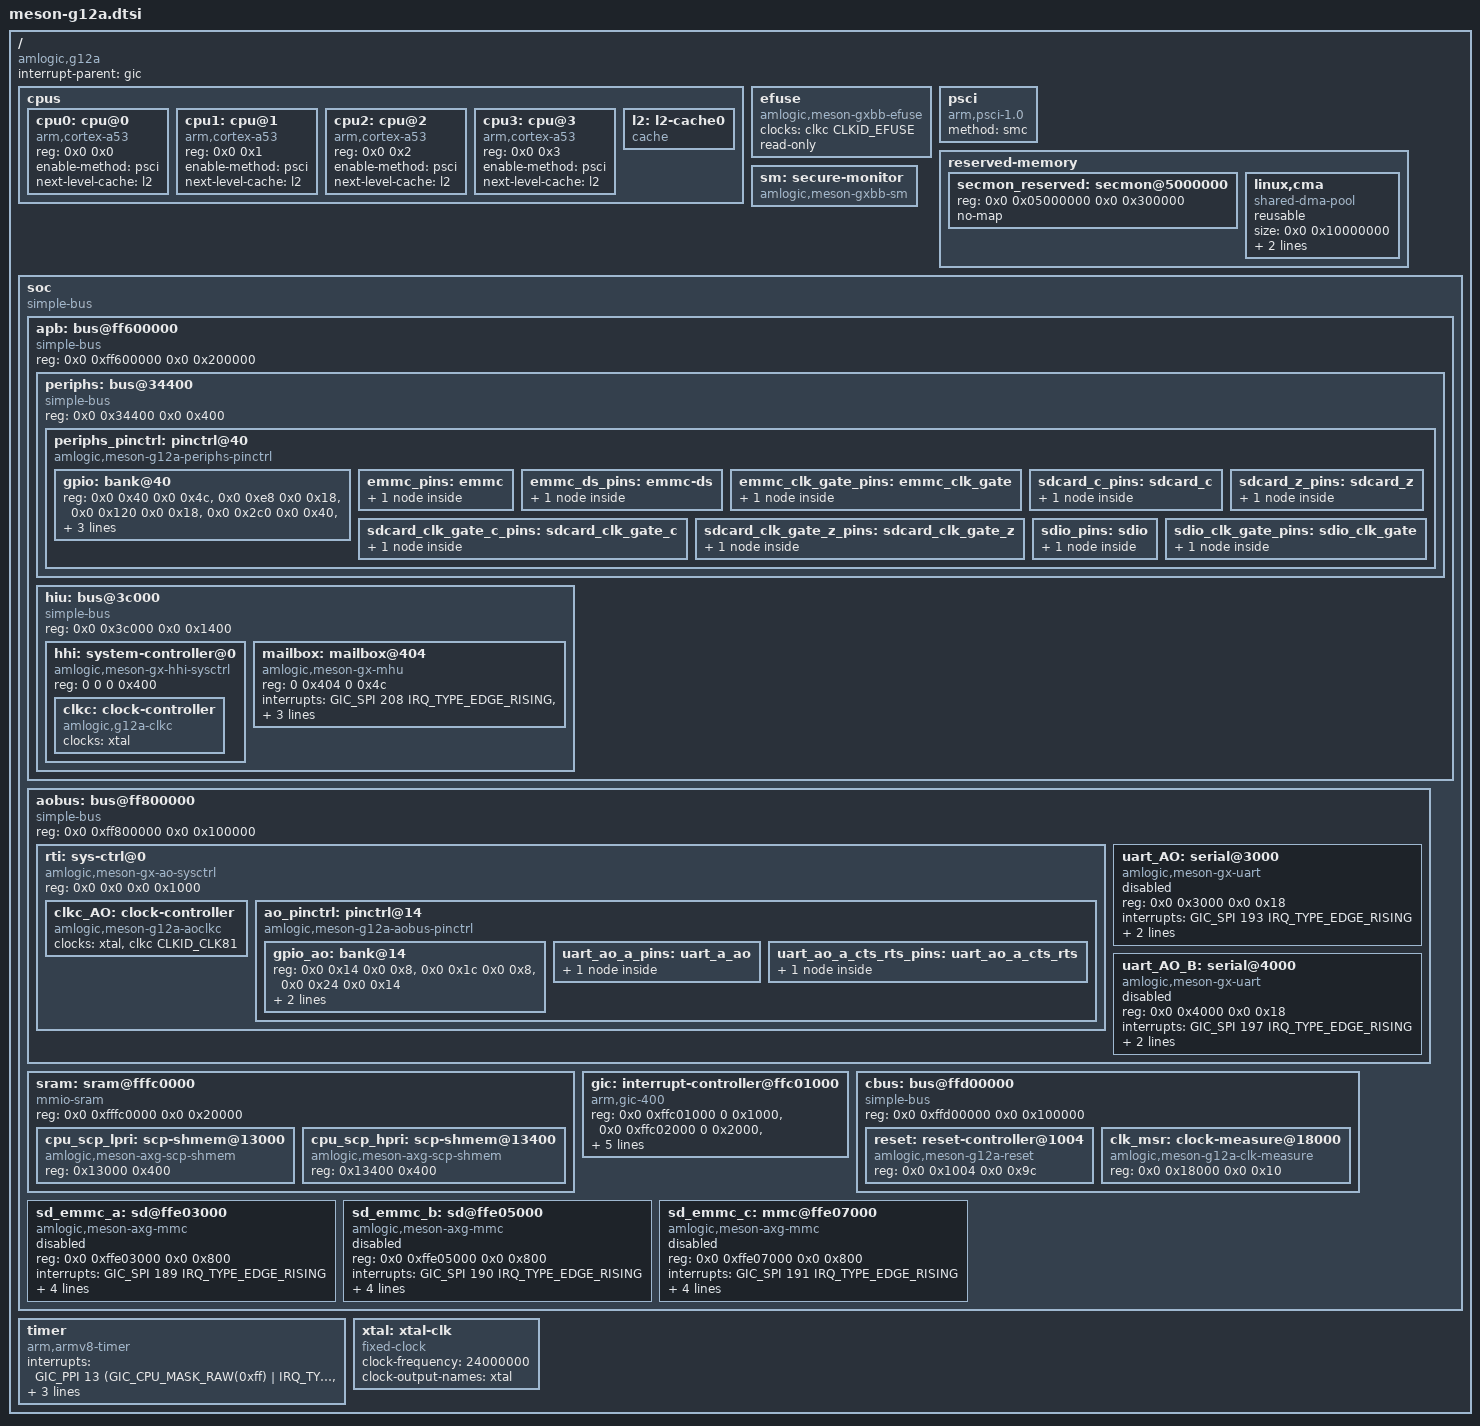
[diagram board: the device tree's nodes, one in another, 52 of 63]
// SPDX-License-Identifier: (GPL-2.0+ OR MIT)
/*
 * Copyright (c) 2018 Amlogic, Inc. All rights reserved.
 */

#include <dt-bindings/gpio/gpio.h>
#include <dt-bindings/clock/g12a-clkc.h>
#include <dt-bindings/gpio/gpio.h>
#include <dt-bindings/gpio/meson-g12a-gpio.h>
#include <dt-bindings/clock/g12a-aoclkc.h>
#include <dt-bindings/reset/g12a-aoclkc.h>
#include <dt-bindings/interrupt-controller/irq.h>
#include <dt-bindings/interrupt-controller/arm-gic.h>
#include <dt-bindings/reset/amlogic,meson-g12a-reset.h>

/ {
	compatible = "amlogic,g12a";

	interrupt-parent = <&gic>;
	#address-cells = <2>;
	#size-cells = <2>;

	cpus {
		#address-cells = <0x2>;
		#size-cells = <0x0>;

		cpu0: cpu@0 {
			device_type = "cpu";
			compatible = "arm,cortex-a53", "arm,armv8";
			reg = <0x0 0x0>;
			enable-method = "psci";
			next-level-cache = <&l2>;
		};

		cpu1: cpu@1 {
			device_type = "cpu";
			compatible = "arm,cortex-a53", "arm,armv8";
			reg = <0x0 0x1>;
			enable-method = "psci";
			next-level-cache = <&l2>;
		};

		cpu2: cpu@2 {
			device_type = "cpu";
			compatible = "arm,cortex-a53", "arm,armv8";
			reg = <0x0 0x2>;
			enable-method = "psci";
			next-level-cache = <&l2>;
		};

		cpu3: cpu@3 {
			device_type = "cpu";
			compatible = "arm,cortex-a53", "arm,armv8";
			reg = <0x0 0x3>;
			enable-method = "psci";
			next-level-cache = <&l2>;
		};

		l2: l2-cache0 {
			compatible = "cache";
		};
	};

	efuse: efuse {
		compatible = "amlogic,meson-gxbb-efuse";
		clocks = <&clkc CLKID_EFUSE>;
		#address-cells = <1>;
		#size-cells = <1>;
		read-only;
	};

	psci {
		compatible = "arm,psci-1.0";
		method = "smc";
	};

	reserved-memory {
		#address-cells = <2>;
		#size-cells = <2>;
		ranges;

		/* 3 MiB reserved for ARM Trusted Firmware (BL31) */
		secmon_reserved: secmon@5000000 {
			reg = <0x0 0x05000000 0x0 0x300000>;
			no-map;
		};

		linux,cma {
			compatible = "shared-dma-pool";
			reusable;
			size = <0x0 0x10000000>;
			alignment = <0x0 0x400000>;
			linux,cma-default;
		};
	};

	sm: secure-monitor {
		compatible = "amlogic,meson-gxbb-sm";
	};

	soc {
		compatible = "simple-bus";
		#address-cells = <2>;
		#size-cells = <2>;
		ranges;

		apb: bus@ff600000 {
			compatible = "simple-bus";
			reg = <0x0 0xff600000 0x0 0x200000>;
			#address-cells = <2>;
			#size-cells = <2>;
			ranges = <0x0 0x0 0x0 0xff600000 0x0 0x200000>;

			periphs: bus@34400 {
				compatible = "simple-bus";
				reg = <0x0 0x34400 0x0 0x400>;
				#address-cells = <2>;
				#size-cells = <2>;
				ranges = <0x0 0x0 0x0 0x34400 0x0 0x400>;

				periphs_pinctrl: pinctrl@40 {
					compatible = "amlogic,meson-g12a-periphs-pinctrl";
					#address-cells = <2>;
					#size-cells = <2>;
					ranges;

					gpio: bank@40 {
						reg = <0x0 0x40  0x0 0x4c>,
						      <0x0 0xe8  0x0 0x18>,
						      <0x0 0x120 0x0 0x18>,
						      <0x0 0x2c0 0x0 0x40>,
						      <0x0 0x340 0x0 0x1c>;
						reg-names = "gpio",
							    "pull",
							    "pull-enable",
							    "mux",
							    "ds";
						gpio-controller;
						#gpio-cells = <2>;
						gpio-ranges = <&periphs_pinctrl 0 0 86>;
					};

					emmc_pins: emmc {
						mux {
							groups = "emmc_nand_d0",
								 "emmc_nand_d1",
								 "emmc_nand_d2",
								 "emmc_nand_d3",
								 "emmc_nand_d4",
								 "emmc_nand_d5",
								 "emmc_nand_d6",
								 "emmc_nand_d7",
								 "emmc_clk",
								 "emmc_cmd";
							function = "emmc";
							bias-disable;
						};
					};

					emmc_ds_pins: emmc-ds {
						mux {
							groups = "emmc_nand_ds";
							function = "emmc";
							bias-disable;
						};
					};

					emmc_clk_gate_pins: emmc_clk_gate {
						mux {
							groups = "BOOT_8";
							function = "gpio_periphs";
							bias-pull-down;
						};
					};

					sdcard_c_pins: sdcard_c {
						mux {
							groups = "sdcard_d0_c",
								 "sdcard_d1_c",
								 "sdcard_d2_c",
								 "sdcard_d3_c",
								 "sdcard_cmd_c",
								 "sdcard_clk_c";
							function = "sdcard";
							bias-disable;
						};
					};

					sdcard_clk_gate_c_pins: sdcard_clk_gate_c {
						mux {
							groups = "GPIOC_4";
							function = "gpio_periphs";
							bias-pull-down;
						};
					};

					sdcard_z_pins: sdcard_z {
						mux {
							groups = "sdcard_d0_z",
								 "sdcard_d1_z",
								 "sdcard_d2_z",
								 "sdcard_d3_z",
								 "sdcard_cmd_z",
								 "sdcard_clk_z";
							function = "sdcard";
							bias-disable;
						};
					};

					sdcard_clk_gate_z_pins: sdcard_clk_gate_z {
						mux {
							groups = "GPIOZ_6";
							function = "gpio_periphs";
							bias-pull-down;
						};
					};

					sdio_pins: sdio {
						mux {
							groups = "sdio_d0",
								 "sdio_d1",
								 "sdio_d2",
								 "sdio_d3",
								 "sdio_cmd",
								 "sdio_clk";
							function = "sdio";
							bias-disable;
						};
					};

					sdio_clk_gate_pins: sdio_clk_gate {
						mux {
							groups = "GPIOX_4";
							function = "gpio_periphs";
							bias-pull-down;
						};
					};
				};
			};

			hiu: bus@3c000 {
				compatible = "simple-bus";
				reg = <0x0 0x3c000 0x0 0x1400>;
				#address-cells = <2>;
				#size-cells = <2>;
				ranges = <0x0 0x0 0x0 0x3c000 0x0 0x1400>;

				hhi: system-controller@0 {
					compatible = "amlogic,meson-gx-hhi-sysctrl",
						     "simple-mfd", "syscon";
					reg = <0 0 0 0x400>;

					clkc: clock-controller {
						compatible = "amlogic,g12a-clkc";
						#clock-cells = <1>;
						clocks = <&xtal>;
						clock-names = "xtal";
					};
				};

				mailbox: mailbox@404 {
					compatible = "amlogic,meson-gx-mhu",
						     "amlogic,meson-gxbb-mhu";
					reg = <0 0x404 0 0x4c>;
					interrupts = <GIC_SPI 208 IRQ_TYPE_EDGE_RISING>,
						     <GIC_SPI 209 IRQ_TYPE_EDGE_RISING>,
						     <GIC_SPI 210 IRQ_TYPE_EDGE_RISING>;
					clocks = <&clkc_AO CLKID_AO_MAILBOX>;
					clock-names = "pclk";
					#mbox-cells = <1>;
				};
			};
		};

		aobus: bus@ff800000 {
			compatible = "simple-bus";
			reg = <0x0 0xff800000 0x0 0x100000>;
			#address-cells = <2>;
			#size-cells = <2>;
			ranges = <0x0 0x0 0x0 0xff800000 0x0 0x100000>;

			rti: sys-ctrl@0 {
				compatible = "amlogic,meson-gx-ao-sysctrl",
					     "simple-mfd", "syscon";
				reg = <0x0 0x0 0x0 0x1000>;
				#address-cells = <2>;
				#size-cells = <2>;
				ranges = <0x0 0x0 0x0 0x0 0x0 0x1000>;

				clkc_AO: clock-controller {
					compatible = "amlogic,meson-g12a-aoclkc";
					#clock-cells = <1>;
					#reset-cells = <1>;
					clocks = <&xtal>, <&clkc CLKID_CLK81>;
					clock-names = "xtal", "mpeg-clk";
				};

				ao_pinctrl: pinctrl@14 {
					compatible = "amlogic,meson-g12a-aobus-pinctrl";
					#address-cells = <2>;
					#size-cells = <2>;
					ranges;

					gpio_ao: bank@14 {
						reg = <0x0 0x14 0x0 0x8>,
						      <0x0 0x1c 0x0 0x8>,
						      <0x0 0x24 0x0 0x14>;
						reg-names = "mux",
							    "ds",
							    "gpio";
						gpio-controller;
						#gpio-cells = <2>;
						gpio-ranges = <&ao_pinctrl 0 0 15>;
					};

					uart_ao_a_pins: uart_a_ao {
						mux {
							groups = "uart_ao_a_tx",
								 "uart_ao_a_rx";
							function = "uart_ao_a";
							bias-disable;
						};
					};

					uart_ao_a_cts_rts_pins: uart_ao_a_cts_rts {
						mux {
							groups = "uart_ao_a_cts",
								 "uart_ao_a_rts";
							function = "uart_ao_a";
							bias-disable;
						};
					};
				};
			};

			uart_AO: serial@3000 {
				compatible = "amlogic,meson-gx-uart",
					     "amlogic,meson-ao-uart";
				reg = <0x0 0x3000 0x0 0x18>;
				interrupts = <GIC_SPI 193 IRQ_TYPE_EDGE_RISING>;
				clocks = <&xtal>, <&clkc_AO CLKID_AO_UART>, <&xtal>;
				clock-names = "xtal", "pclk", "baud";
				reset = <&clkc_AO RESET_AO_UART>;
				status = "disabled";
			};

			uart_AO_B: serial@4000 {
				compatible = "amlogic,meson-gx-uart",
					     "amlogic,meson-ao-uart";
				reg = <0x0 0x4000 0x0 0x18>;
				interrupts = <GIC_SPI 197 IRQ_TYPE_EDGE_RISING>;
				clocks = <&xtal>, <&clkc_AO CLKID_AO_UART2>, <&xtal>;
				clock-names = "xtal", "pclk", "baud";
				reset = <&clkc_AO RESET_AO_UART2>;
				status = "disabled";
			};
		};

		sram: sram@fffc0000 {
			compatible = "mmio-sram";
			reg = <0x0 0xfffc0000 0x0 0x20000>;
			#address-cells = <1>;
			#size-cells = <1>;
			ranges = <0 0x0 0xfffc0000 0x20000>;

			cpu_scp_lpri: scp-shmem@13000 {
				compatible = "amlogic,meson-axg-scp-shmem";
				reg = <0x13000 0x400>;
			};

			cpu_scp_hpri: scp-shmem@13400 {
				compatible = "amlogic,meson-axg-scp-shmem";
				reg = <0x13400 0x400>;
			};
		};

		gic: interrupt-controller@ffc01000 {
			compatible = "arm,gic-400";
			reg = <0x0 0xffc01000 0 0x1000>,
			      <0x0 0xffc02000 0 0x2000>,
			      <0x0 0xffc04000 0 0x2000>,
			      <0x0 0xffc06000 0 0x2000>;
			interrupt-controller;
			interrupts = <GIC_PPI 9
				(GIC_CPU_MASK_SIMPLE(8) | IRQ_TYPE_LEVEL_HIGH)>;
			#interrupt-cells = <3>;
			#address-cells = <0>;
		};

		cbus: bus@ffd00000 {
			compatible = "simple-bus";
			reg = <0x0 0xffd00000 0x0 0x100000>;
			#address-cells = <2>;
			#size-cells = <2>;
			ranges = <0x0 0x0 0x0 0xffd00000 0x0 0x100000>;

			reset: reset-controller@1004 {
				compatible = "amlogic,meson-g12a-reset",
					     "amlogic,meson-axg-reset";
				reg = <0x0 0x1004 0x0 0x9c>;
				#reset-cells = <1>;
			};

			clk_msr: clock-measure@18000 {
				compatible = "amlogic,meson-g12a-clk-measure";
				reg = <0x0 0x18000 0x0 0x10>;
			};
		};

		sd_emmc_a: sd@ffe03000 {
			compatible = "amlogic,meson-axg-mmc";
			reg = <0x0 0xffe03000 0x0 0x800>;
			interrupts = <GIC_SPI 189 IRQ_TYPE_EDGE_RISING>;
			status = "disabled";
			clocks = <&clkc CLKID_SD_EMMC_A>,
				 <&clkc CLKID_SD_EMMC_A_CLK0>,
				 <&clkc CLKID_FCLK_DIV2>;
			clock-names = "core", "clkin0", "clkin1";
			resets = <&reset RESET_SD_EMMC_A>;
		};

		sd_emmc_b: sd@ffe05000 {
			compatible = "amlogic,meson-axg-mmc";
			reg = <0x0 0xffe05000 0x0 0x800>;
			interrupts = <GIC_SPI 190 IRQ_TYPE_EDGE_RISING>;
			status = "disabled";
			clocks = <&clkc CLKID_SD_EMMC_B>,
				 <&clkc CLKID_SD_EMMC_B_CLK0>,
				 <&clkc CLKID_FCLK_DIV2>;
			clock-names = "core", "clkin0", "clkin1";
			resets = <&reset RESET_SD_EMMC_B>;
		};

		sd_emmc_c: mmc@ffe07000 {
			compatible = "amlogic,meson-axg-mmc";
			reg = <0x0 0xffe07000 0x0 0x800>;
			interrupts = <GIC_SPI 191 IRQ_TYPE_EDGE_RISING>;
			status = "disabled";
			clocks = <&clkc CLKID_SD_EMMC_C>,
				 <&clkc CLKID_SD_EMMC_C_CLK0>,
				 <&clkc CLKID_FCLK_DIV2>;
			clock-names = "core", "clkin0", "clkin1";
			resets = <&reset RESET_SD_EMMC_C>;
		};
	};

	timer {
		compatible = "arm,armv8-timer";
		interrupts = <GIC_PPI 13
			(GIC_CPU_MASK_RAW(0xff) | IRQ_TYPE_LEVEL_LOW)>,
			     <GIC_PPI 14
			(GIC_CPU_MASK_RAW(0xff) | IRQ_TYPE_LEVEL_LOW)>,
			     <GIC_PPI 11
			(GIC_CPU_MASK_RAW(0xff) | IRQ_TYPE_LEVEL_LOW)>,
			     <GIC_PPI 10
			(GIC_CPU_MASK_RAW(0xff) | IRQ_TYPE_LEVEL_LOW)>;
	};

	xtal: xtal-clk {
		compatible = "fixed-clock";
		clock-frequency = <24000000>;
		clock-output-names = "xtal";
		#clock-cells = <0>;
	};

};
